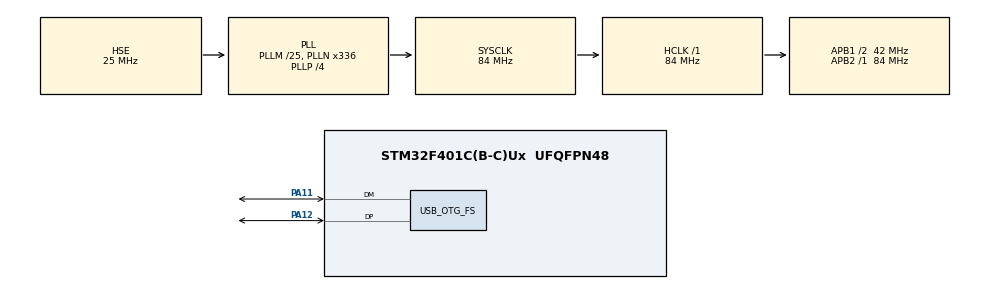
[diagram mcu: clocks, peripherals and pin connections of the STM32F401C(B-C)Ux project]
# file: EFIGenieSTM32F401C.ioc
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ADC1.Channel-1\#ChannelRegularConversion=ADC_CHANNEL_TEMPSENSOR
ADC1.NbrOfConversionFlag=1
ADC1.Rank-1\#ChannelRegularConversion=1
ADC1.SamplingTime-1\#ChannelRegularConversion=ADC_SAMPLETIME_3CYCLES
ADC1.master=1
Mcu.Family=STM32F4
Mcu.Name=STM32F401C(B-C)Ux
Mcu.Package=UFQFPN48
NVIC.OTG_FS_IRQn=true\:14\:0\:true\:false\:true\:false\:true
NVIC.PriorityGroup=NVIC_PRIORITYGROUP_4
PA11.Mode=Device_Only
PA11.Signal=USB_OTG_FS_DM
PA12.Mode=Device_Only
PA12.Signal=USB_OTG_FS_DP
PA13.Mode=Serial_Wire
PA13.Signal=SYS_JTMS-SWDIO
PA14.Mode=Serial_Wire
PA14.Signal=SYS_JTCK-SWCLK
PH0\ -\ OSC_IN.Mode=HSE-External-Oscillator
PH0\ -\ OSC_IN.Signal=RCC_OSC_IN
PH1\ -\ OSC_OUT.Mode=HSE-External-Oscillator
PH1\ -\ OSC_OUT.Signal=RCC_OSC_OUT
ProjectManager.HeapSize=0x200
ProjectManager.StackSize=0x400
ProjectManager.TargetToolchain=Makefile
RCC.48MHZClocksFreq_Value=48000000
RCC.AHBFreq_Value=84000000
RCC.APB1CLKDivider=RCC_HCLK_DIV2
RCC.APB1Freq_Value=42000000
RCC.APB1TimFreq_Value=84000000
RCC.APB2Freq_Value=84000000
RCC.APB2TimFreq_Value=84000000
RCC.CortexFreq_Value=84000000
RCC.HCLKFreq_Value=84000000
RCC.HSE_VALUE=25000000
RCC.HSI_VALUE=16000000
RCC.LSE_VALUE=32768
RCC.PLLM=25
RCC.PLLN=336
RCC.PLLP=RCC_PLLP_DIV4
RCC.PLLQ=7
RCC.SYSCLKFreq_VALUE=84000000
RCC.SYSCLKSource=RCC_SYSCLKSOURCE_PLLCLK
RCC.VCOOutputFreq_Value=336000000
USB_DEVICE.CLASS_NAME_FS=CDC
USB_DEVICE.VirtualMode=Cdc
USB_DEVICE.VirtualModeFS=Cdc_FS
USB_OTG_FS.VirtualMode=Device_Only
VP_ADC1_TempSens_Input.Mode=IN-TempSens
VP_RTC_VS_RTC_Activate.Mode=RTC_Enabled
VP_TIM1_VS_ClockSourceINT.Mode=Internal
VP_USB_DEVICE_VS_USB_DEVICE_CDC_FS.Mode=CDC_FS
board=custom

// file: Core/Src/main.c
/* USER CODE BEGIN Header */
/**
  ******************************************************************************
  * @file           : main.c
  * @brief          : Main program body
  ******************************************************************************
  * @attention
  *
  * <h2><center>&copy; Copyright (c) 2021 STMicroelectronics.
  * All rights reserved.</center></h2>
  *
  * This software component is licensed by ST under Ultimate Liberty license
  * SLA0044, the "License"; You may not use this file except in compliance with
  * the License. You may obtain a copy of the License at:
  *                             www.st.com/SLA0044
  *
  ******************************************************************************
  */
/* USER CODE END Header */
#include "main.h"
#include "usb_device.h"

/* USER CODE BEGIN Includes */
#include "Entry.h"
/* USER CODE END Includes */

ADC_HandleTypeDef hadc1;

RTC_HandleTypeDef hrtc;

TIM_HandleTypeDef htim1;

void SystemClock_Config(void);
static void MX_GPIO_Init(void);
static void MX_ADC1_Init(void);
static void MX_TIM1_Init(void);
static void MX_RTC_Init(void);

int main(void)
{

  /* MCU Configuration--------------------------------------------------------*/

  /* Reset of all peripherals, Initializes the Flash interface and the Systick. */
  HAL_Init();

  /* Configure the system clock */
  SystemClock_Config();

  /* Initialize all configured peripherals */
  MX_GPIO_Init();
  MX_ADC1_Init();
  MX_TIM1_Init();
  MX_USB_DEVICE_Init();
  MX_RTC_Init();
  /* USER CODE BEGIN 2 */
  Setup();
  /* USER CODE END 2 */

  /* Infinite loop */
  /* USER CODE BEGIN WHILE */
  while (1)
  {
    Loop();
    /* USER CODE END WHILE */

  }
}

void SystemClock_Config(void)
{
  RCC_OscInitTypeDef RCC_OscInitStruct = {0};
  RCC_ClkInitTypeDef RCC_ClkInitStruct = {0};
  RCC_PeriphCLKInitTypeDef PeriphClkInitStruct = {0};

  /** Configure the main internal regulator output voltage
  */
  __HAL_RCC_PWR_CLK_ENABLE();
  __HAL_PWR_VOLTAGESCALING_CONFIG(PWR_REGULATOR_VOLTAGE_SCALE2);
  /** Initializes the RCC Oscillators according to the specified parameters
  * in the RCC_OscInitTypeDef structure.
  */
  RCC_OscInitStruct.OscillatorType = RCC_OSCILLATORTYPE_LSI|RCC_OSCILLATORTYPE_HSE;
  RCC_OscInitStruct.HSEState = RCC_HSE_ON;
  RCC_OscInitStruct.LSIState = RCC_LSI_ON;
  RCC_OscInitStruct.PLL.PLLState = RCC_PLL_ON;
  RCC_OscInitStruct.PLL.PLLSource = RCC_PLLSOURCE_HSE;
  RCC_OscInitStruct.PLL.PLLM = 25;
  RCC_OscInitStruct.PLL.PLLN = 336;
  RCC_OscInitStruct.PLL.PLLP = RCC_PLLP_DIV4;
  RCC_OscInitStruct.PLL.PLLQ = 7;
  if (HAL_RCC_OscConfig(&RCC_OscInitStruct) != HAL_OK)
  {
    Error_Handler();
  }
  /** Initializes the CPU, AHB and APB buses clocks
  */
  RCC_ClkInitStruct.ClockType = RCC_CLOCKTYPE_HCLK|RCC_CLOCKTYPE_SYSCLK
                              |RCC_CLOCKTYPE_PCLK1|RCC_CLOCKTYPE_PCLK2;
  RCC_ClkInitStruct.SYSCLKSource = RCC_SYSCLKSOURCE_PLLCLK;
  RCC_ClkInitStruct.AHBCLKDivider = RCC_SYSCLK_DIV1;
  RCC_ClkInitStruct.APB1CLKDivider = RCC_HCLK_DIV2;
  RCC_ClkInitStruct.APB2CLKDivider = RCC_HCLK_DIV1;

  if (HAL_RCC_ClockConfig(&RCC_ClkInitStruct, FLASH_LATENCY_2) != HAL_OK)
  {
    Error_Handler();
  }
  PeriphClkInitStruct.PeriphClockSelection = RCC_PERIPHCLK_RTC;
  PeriphClkInitStruct.RTCClockSelection = RCC_RTCCLKSOURCE_LSI;
  if (HAL_RCCEx_PeriphCLKConfig(&PeriphClkInitStruct) != HAL_OK)
  {
    Error_Handler();
  }
}

static void MX_ADC1_Init(void)
{

  ADC_ChannelConfTypeDef sConfig = {0};

  /** Configure the global features of the ADC (Clock, Resolution, Data Alignment and number of conversion)
  */
  hadc1.Instance = ADC1;
  hadc1.Init.ClockPrescaler = ADC_CLOCK_SYNC_PCLK_DIV4;
  hadc1.Init.Resolution = ADC_RESOLUTION_12B;
  hadc1.Init.ScanConvMode = DISABLE;
  hadc1.Init.ContinuousConvMode = DISABLE;
  hadc1.Init.DiscontinuousConvMode = DISABLE;
  hadc1.Init.ExternalTrigConvEdge = ADC_EXTERNALTRIGCONVEDGE_NONE;
  hadc1.Init.ExternalTrigConv = ADC_SOFTWARE_START;
  hadc1.Init.DataAlign = ADC_DATAALIGN_RIGHT;
  hadc1.Init.NbrOfConversion = 1;
  hadc1.Init.DMAContinuousRequests = DISABLE;
  hadc1.Init.EOCSelection = ADC_EOC_SINGLE_CONV;
  if (HAL_ADC_Init(&hadc1) != HAL_OK)
  {
    Error_Handler();
  }
  /** Configure for the selected ADC regular channel its corresponding rank in the sequencer and its sample time.
  */
  sConfig.Channel = ADC_CHANNEL_TEMPSENSOR;
  sConfig.Rank = 1;
  sConfig.SamplingTime = ADC_SAMPLETIME_3CYCLES;
  if (HAL_ADC_ConfigChannel(&hadc1, &sConfig) != HAL_OK)
  {
    Error_Handler();
  }

}

static void MX_RTC_Init(void)
{

  /** Initialize RTC Only
  */
  hrtc.Instance = RTC;
  hrtc.Init.HourFormat = RTC_HOURFORMAT_24;
  hrtc.Init.AsynchPrediv = 127;
  hrtc.Init.SynchPrediv = 255;
  hrtc.Init.OutPut = RTC_OUTPUT_DISABLE;
  hrtc.Init.OutPutPolarity = RTC_OUTPUT_POLARITY_HIGH;
  hrtc.Init.OutPutType = RTC_OUTPUT_TYPE_OPENDRAIN;
  if (HAL_RTC_Init(&hrtc) != HAL_OK)
  {
    Error_Handler();
  }

}

static void MX_TIM1_Init(void)
{

  TIM_ClockConfigTypeDef sClockSourceConfig = {0};
  TIM_MasterConfigTypeDef sMasterConfig = {0};

  htim1.Instance = TIM1;
  htim1.Init.Prescaler = 0;
  htim1.Init.CounterMode = TIM_COUNTERMODE_UP;
  htim1.Init.Period = 65535;
  htim1.Init.ClockDivision = TIM_CLOCKDIVISION_DIV1;
  htim1.Init.RepetitionCounter = 0;
  htim1.Init.AutoReloadPreload = TIM_AUTORELOAD_PRELOAD_DISABLE;
  if (HAL_TIM_Base_Init(&htim1) != HAL_OK)
  {
    Error_Handler();
  }
  sClockSourceConfig.ClockSource = TIM_CLOCKSOURCE_INTERNAL;
  if (HAL_TIM_ConfigClockSource(&htim1, &sClockSourceConfig) != HAL_OK)
  {
    Error_Handler();
  }
  sMasterConfig.MasterOutputTrigger = TIM_TRGO_RESET;
  sMasterConfig.MasterSlaveMode = TIM_MASTERSLAVEMODE_DISABLE;
  if (HAL_TIMEx_MasterConfigSynchronization(&htim1, &sMasterConfig) != HAL_OK)
  {
    Error_Handler();
  }

}

static void MX_GPIO_Init(void)
{

  /* GPIO Ports Clock Enable */
  __HAL_RCC_GPIOH_CLK_ENABLE();
  __HAL_RCC_GPIOA_CLK_ENABLE();

}

void Error_Handler(void)
{
  __disable_irq();
  while (1)
  {
  }
}

/************************ (C) COPYRIGHT STMicroelectronics *****END OF FILE****/
